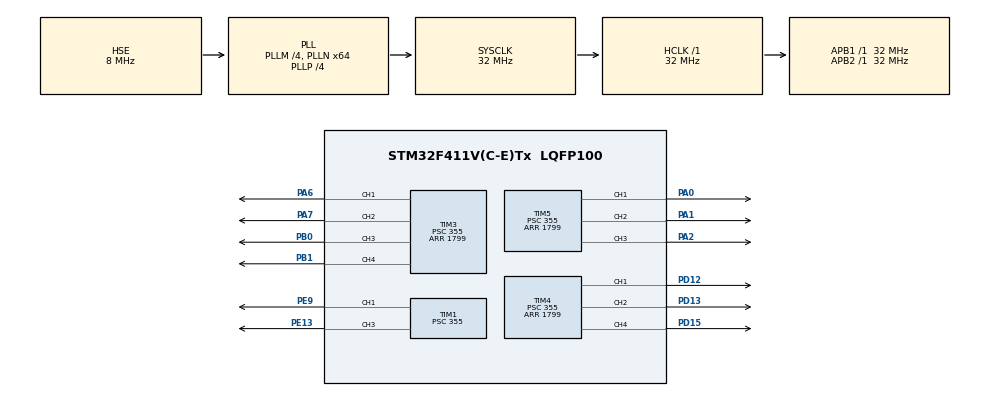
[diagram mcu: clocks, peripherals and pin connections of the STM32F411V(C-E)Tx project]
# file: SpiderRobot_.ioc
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Mcu.Family=STM32F4
Mcu.Name=STM32F411V(C-E)Tx
Mcu.Package=LQFP100
NVIC.PriorityGroup=NVIC_PRIORITYGROUP_4
PA0-WKUP.Signal=S_TIM5_CH1
PA1.Signal=S_TIM5_CH2
PA13.Mode=Serial_Wire
PA13.Signal=SYS_JTMS-SWDIO
PA14.Mode=Serial_Wire
PA14.Signal=SYS_JTCK-SWCLK
PA2.Signal=S_TIM5_CH3
PA6.Signal=S_TIM3_CH1
PA7.Signal=S_TIM3_CH2
PB0.Signal=S_TIM3_CH3
PB1.Signal=S_TIM3_CH4
PD12.Signal=S_TIM4_CH1
PD13.Signal=S_TIM4_CH2
PD15.Signal=S_TIM4_CH4
PE13.Signal=S_TIM1_CH3
PE9.Signal=S_TIM1_CH1
PH0\ -\ OSC_IN.Mode=HSE-External-Oscillator
PH0\ -\ OSC_IN.Signal=RCC_OSC_IN
PH1\ -\ OSC_OUT.Mode=HSE-External-Oscillator
PH1\ -\ OSC_OUT.Signal=RCC_OSC_OUT
ProjectManager.HeapSize=0x200
ProjectManager.StackSize=0x400
ProjectManager.TargetToolchain=STM32CubeIDE
RCC.48MHZClocksFreq_Value=32000000
RCC.AHBFreq_Value=32000000
RCC.APB1Freq_Value=32000000
RCC.APB1TimFreq_Value=32000000
RCC.APB2Freq_Value=32000000
RCC.APB2TimFreq_Value=32000000
RCC.CortexFreq_Value=32000000
RCC.HCLKFreq_Value=32000000
RCC.HSE_VALUE=8000000
RCC.HSI_VALUE=16000000
RCC.LSE_VALUE=32768
RCC.PLLM=4
RCC.PLLN=64
RCC.PLLP=RCC_PLLP_DIV4
RCC.PLLSourceVirtual=RCC_PLLSOURCE_HSE
RCC.SYSCLKFreq_VALUE=32000000
RCC.SYSCLKSource=RCC_SYSCLKSOURCE_PLLCLK
RCC.VCOOutputFreq_Value=128000000
SH.S_TIM1_CH1.0=TIM1_CH1,PWM Generation1 CH1
SH.S_TIM1_CH3.0=TIM1_CH3,PWM Generation3 CH3
SH.S_TIM3_CH1.0=TIM3_CH1,PWM Generation1 CH1
SH.S_TIM3_CH2.0=TIM3_CH2,PWM Generation2 CH2
SH.S_TIM3_CH3.0=TIM3_CH3,PWM Generation3 CH3
SH.S_TIM3_CH4.0=TIM3_CH4,PWM Generation4 CH4
SH.S_TIM4_CH1.0=TIM4_CH1,PWM Generation1 CH1
SH.S_TIM4_CH2.0=TIM4_CH2,PWM Generation2 CH2
SH.S_TIM4_CH4.0=TIM4_CH4,PWM Generation4 CH4
SH.S_TIM5_CH1.0=TIM5_CH1,PWM Generation1 CH1
SH.S_TIM5_CH2.0=TIM5_CH2,PWM Generation2 CH2
SH.S_TIM5_CH3.0=TIM5_CH3,PWM Generation3 CH3
TIM1.Channel-PWM\ Generation1\ CH1=TIM_CHANNEL_1
TIM1.Channel-PWM\ Generation3\ CH3=TIM_CHANNEL_3
TIM1.Period=1799
TIM1.Prescaler=355
TIM3.Channel-PWM\ Generation1\ CH1=TIM_CHANNEL_1
TIM3.Channel-PWM\ Generation2\ CH2=TIM_CHANNEL_2
TIM3.Channel-PWM\ Generation3\ CH3=TIM_CHANNEL_3
TIM3.Channel-PWM\ Generation4\ CH4=TIM_CHANNEL_4
TIM3.Period=1799
TIM3.Prescaler=355
TIM4.Channel-PWM\ Generation1\ CH1=TIM_CHANNEL_1
TIM4.Channel-PWM\ Generation2\ CH2=TIM_CHANNEL_2
TIM4.Channel-PWM\ Generation3\ CH3=TIM_CHANNEL_3
TIM4.Channel-PWM\ Generation4\ CH4=TIM_CHANNEL_4
TIM4.Period=1799
TIM4.Prescaler=355
TIM5.Channel-PWM\ Generation1\ CH1=TIM_CHANNEL_1
TIM5.Channel-PWM\ Generation2\ CH2=TIM_CHANNEL_2
TIM5.Channel-PWM\ Generation3\ CH3=TIM_CHANNEL_3
TIM5.Period=1799
TIM5.Prescaler=355
board=custom

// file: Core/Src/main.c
/* USER CODE BEGIN Header */
/**
  ******************************************************************************
  * @file           : main.c
  * @brief          : Main program body
  ******************************************************************************
  * @attention
  *
  * Copyright (c) 2022 STMicroelectronics.
  * All rights reserved.
  *
  * This software is licensed under terms that can be found in the LICENSE file
  * in the root directory of this software component.
  * If no LICENSE file comes with this software, it is provided AS-IS.
  *
  ******************************************************************************
  */
/* USER CODE END Header */
#include "SpiderDriver.h"
#include "main.h"

TIM_HandleTypeDef htim1;
TIM_HandleTypeDef htim3;
TIM_HandleTypeDef htim4;
TIM_HandleTypeDef htim5;

void SystemClock_Config(void);
static void MX_GPIO_Init(void);
static void MX_TIM1_Init(void);
static void MX_TIM3_Init(void);
static void MX_TIM4_Init(void);
static void MX_TIM5_Init(void);

int main(void)
{

  /* MCU Configuration--------------------------------------------------------*/

  /* Reset of all peripherals, Initializes the Flash interface and the Systick. */
  HAL_Init();

  /* Configure the system clock */
  SystemClock_Config();

  /* Initialize all configured peripherals */
  MX_GPIO_Init();
  MX_TIM1_Init();
  MX_TIM3_Init();
  MX_TIM4_Init();
  MX_TIM5_Init();

  /* USER CODE BEGIN 2 */

  robot_tims_init();
  HAL_Delay(50);

  robot_all_leg_90();
  HAL_Delay(1000);

  initPosition();
  HAL_Delay(1000);

  /* USER CODE END 2 */

  /* Infinite loop */
  while (1)
  {

    /* USER CODE BEGIN 3 */

	  moveForward();

  }
  /* USER CODE END 3 */
}

void SystemClock_Config(void)
{
  RCC_OscInitTypeDef RCC_OscInitStruct = {0};
  RCC_ClkInitTypeDef RCC_ClkInitStruct = {0};

  /** Configure the main internal regulator output voltage
  */
  __HAL_RCC_PWR_CLK_ENABLE();
  __HAL_PWR_VOLTAGESCALING_CONFIG(PWR_REGULATOR_VOLTAGE_SCALE1);

  /** Initializes the RCC Oscillators according to the specified parameters
  * in the RCC_OscInitTypeDef structure.
  */
  RCC_OscInitStruct.OscillatorType = RCC_OSCILLATORTYPE_HSE;
  RCC_OscInitStruct.HSEState = RCC_HSE_ON;
  RCC_OscInitStruct.PLL.PLLState = RCC_PLL_ON;
  RCC_OscInitStruct.PLL.PLLSource = RCC_PLLSOURCE_HSE;
  RCC_OscInitStruct.PLL.PLLM = 4;
  RCC_OscInitStruct.PLL.PLLN = 64;
  RCC_OscInitStruct.PLL.PLLP = RCC_PLLP_DIV4;
  RCC_OscInitStruct.PLL.PLLQ = 4;
  if (HAL_RCC_OscConfig(&RCC_OscInitStruct) != HAL_OK)
  {
    Error_Handler();
  }

  /** Initializes the CPU, AHB and APB buses clocks
  */
  RCC_ClkInitStruct.ClockType = RCC_CLOCKTYPE_HCLK|RCC_CLOCKTYPE_SYSCLK
                              |RCC_CLOCKTYPE_PCLK1|RCC_CLOCKTYPE_PCLK2;
  RCC_ClkInitStruct.SYSCLKSource = RCC_SYSCLKSOURCE_PLLCLK;
  RCC_ClkInitStruct.AHBCLKDivider = RCC_SYSCLK_DIV1;
  RCC_ClkInitStruct.APB1CLKDivider = RCC_HCLK_DIV1;
  RCC_ClkInitStruct.APB2CLKDivider = RCC_HCLK_DIV1;

  if (HAL_RCC_ClockConfig(&RCC_ClkInitStruct, FLASH_LATENCY_1) != HAL_OK)
  {
    Error_Handler();
  }
}

static void MX_TIM1_Init(void)
{

  TIM_MasterConfigTypeDef sMasterConfig = {0};
  TIM_OC_InitTypeDef sConfigOC = {0};
  TIM_BreakDeadTimeConfigTypeDef sBreakDeadTimeConfig = {0};

  htim1.Instance = TIM1;
  htim1.Init.Prescaler = 355;
  htim1.Init.CounterMode = TIM_COUNTERMODE_UP;
  htim1.Init.Period = 1799;
  htim1.Init.ClockDivision = TIM_CLOCKDIVISION_DIV1;
  htim1.Init.RepetitionCounter = 0;
  htim1.Init.AutoReloadPreload = TIM_AUTORELOAD_PRELOAD_DISABLE;
  if (HAL_TIM_PWM_Init(&htim1) != HAL_OK)
  {
    Error_Handler();
  }
  sMasterConfig.MasterOutputTrigger = TIM_TRGO_RESET;
  sMasterConfig.MasterSlaveMode = TIM_MASTERSLAVEMODE_DISABLE;
  if (HAL_TIMEx_MasterConfigSynchronization(&htim1, &sMasterConfig) != HAL_OK)
  {
    Error_Handler();
  }
  sConfigOC.OCMode = TIM_OCMODE_PWM1;
  sConfigOC.Pulse = 0;
  sConfigOC.OCPolarity = TIM_OCPOLARITY_HIGH;
  sConfigOC.OCNPolarity = TIM_OCNPOLARITY_HIGH;
  sConfigOC.OCFastMode = TIM_OCFAST_DISABLE;
  sConfigOC.OCIdleState = TIM_OCIDLESTATE_RESET;
  sConfigOC.OCNIdleState = TIM_OCNIDLESTATE_RESET;
  if (HAL_TIM_PWM_ConfigChannel(&htim1, &sConfigOC, TIM_CHANNEL_1) != HAL_OK)
  {
    Error_Handler();
  }
  if (HAL_TIM_PWM_ConfigChannel(&htim1, &sConfigOC, TIM_CHANNEL_3) != HAL_OK)
  {
    Error_Handler();
  }
  sBreakDeadTimeConfig.OffStateRunMode = TIM_OSSR_DISABLE;
  sBreakDeadTimeConfig.OffStateIDLEMode = TIM_OSSI_DISABLE;
  sBreakDeadTimeConfig.LockLevel = TIM_LOCKLEVEL_OFF;
  sBreakDeadTimeConfig.DeadTime = 0;
  sBreakDeadTimeConfig.BreakState = TIM_BREAK_DISABLE;
  sBreakDeadTimeConfig.BreakPolarity = TIM_BREAKPOLARITY_HIGH;
  sBreakDeadTimeConfig.AutomaticOutput = TIM_AUTOMATICOUTPUT_DISABLE;
  if (HAL_TIMEx_ConfigBreakDeadTime(&htim1, &sBreakDeadTimeConfig) != HAL_OK)
  {
    Error_Handler();
  }
  HAL_TIM_MspPostInit(&htim1);

}

static void MX_TIM3_Init(void)
{

  TIM_MasterConfigTypeDef sMasterConfig = {0};
  TIM_OC_InitTypeDef sConfigOC = {0};

  htim3.Instance = TIM3;
  htim3.Init.Prescaler = 355;
  htim3.Init.CounterMode = TIM_COUNTERMODE_UP;
  htim3.Init.Period = 1799;
  htim3.Init.ClockDivision = TIM_CLOCKDIVISION_DIV1;
  htim3.Init.AutoReloadPreload = TIM_AUTORELOAD_PRELOAD_DISABLE;
  if (HAL_TIM_PWM_Init(&htim3) != HAL_OK)
  {
    Error_Handler();
  }
  sMasterConfig.MasterOutputTrigger = TIM_TRGO_RESET;
  sMasterConfig.MasterSlaveMode = TIM_MASTERSLAVEMODE_DISABLE;
  if (HAL_TIMEx_MasterConfigSynchronization(&htim3, &sMasterConfig) != HAL_OK)
  {
    Error_Handler();
  }
  sConfigOC.OCMode = TIM_OCMODE_PWM1;
  sConfigOC.Pulse = 0;
  sConfigOC.OCPolarity = TIM_OCPOLARITY_HIGH;
  sConfigOC.OCFastMode = TIM_OCFAST_DISABLE;
  if (HAL_TIM_PWM_ConfigChannel(&htim3, &sConfigOC, TIM_CHANNEL_1) != HAL_OK)
  {
    Error_Handler();
  }
  if (HAL_TIM_PWM_ConfigChannel(&htim3, &sConfigOC, TIM_CHANNEL_2) != HAL_OK)
  {
    Error_Handler();
  }
  if (HAL_TIM_PWM_ConfigChannel(&htim3, &sConfigOC, TIM_CHANNEL_3) != HAL_OK)
  {
    Error_Handler();
  }
  if (HAL_TIM_PWM_ConfigChannel(&htim3, &sConfigOC, TIM_CHANNEL_4) != HAL_OK)
  {
    Error_Handler();
  }
  HAL_TIM_MspPostInit(&htim3);

}

static void MX_TIM4_Init(void)
{

  TIM_MasterConfigTypeDef sMasterConfig = {0};
  TIM_OC_InitTypeDef sConfigOC = {0};

  htim4.Instance = TIM4;
  htim4.Init.Prescaler = 355;
  htim4.Init.CounterMode = TIM_COUNTERMODE_UP;
  htim4.Init.Period = 1799;
  htim4.Init.ClockDivision = TIM_CLOCKDIVISION_DIV1;
  htim4.Init.AutoReloadPreload = TIM_AUTORELOAD_PRELOAD_DISABLE;
  if (HAL_TIM_PWM_Init(&htim4) != HAL_OK)
  {
    Error_Handler();
  }
  sMasterConfig.MasterOutputTrigger = TIM_TRGO_RESET;
  sMasterConfig.MasterSlaveMode = TIM_MASTERSLAVEMODE_DISABLE;
  if (HAL_TIMEx_MasterConfigSynchronization(&htim4, &sMasterConfig) != HAL_OK)
  {
    Error_Handler();
  }
  sConfigOC.OCMode = TIM_OCMODE_PWM1;
  sConfigOC.Pulse = 0;
  sConfigOC.OCPolarity = TIM_OCPOLARITY_HIGH;
  sConfigOC.OCFastMode = TIM_OCFAST_DISABLE;
  if (HAL_TIM_PWM_ConfigChannel(&htim4, &sConfigOC, TIM_CHANNEL_1) != HAL_OK)
  {
    Error_Handler();
  }
  if (HAL_TIM_PWM_ConfigChannel(&htim4, &sConfigOC, TIM_CHANNEL_2) != HAL_OK)
  {
    Error_Handler();
  }
  if (HAL_TIM_PWM_ConfigChannel(&htim4, &sConfigOC, TIM_CHANNEL_4) != HAL_OK)
  {
    Error_Handler();
  }
  HAL_TIM_MspPostInit(&htim4);

}

static void MX_TIM5_Init(void)
{

  TIM_MasterConfigTypeDef sMasterConfig = {0};
  TIM_OC_InitTypeDef sConfigOC = {0};

  htim5.Instance = TIM5;
  htim5.Init.Prescaler = 355;
  htim5.Init.CounterMode = TIM_COUNTERMODE_UP;
  htim5.Init.Period = 1799;
  htim5.Init.ClockDivision = TIM_CLOCKDIVISION_DIV1;
  htim5.Init.AutoReloadPreload = TIM_AUTORELOAD_PRELOAD_DISABLE;
  if (HAL_TIM_PWM_Init(&htim5) != HAL_OK)
  {
    Error_Handler();
  }
  sMasterConfig.MasterOutputTrigger = TIM_TRGO_RESET;
  sMasterConfig.MasterSlaveMode = TIM_MASTERSLAVEMODE_DISABLE;
  if (HAL_TIMEx_MasterConfigSynchronization(&htim5, &sMasterConfig) != HAL_OK)
  {
    Error_Handler();
  }
  sConfigOC.OCMode = TIM_OCMODE_PWM1;
  sConfigOC.Pulse = 0;
  sConfigOC.OCPolarity = TIM_OCPOLARITY_HIGH;
  sConfigOC.OCFastMode = TIM_OCFAST_DISABLE;
  if (HAL_TIM_PWM_ConfigChannel(&htim5, &sConfigOC, TIM_CHANNEL_1) != HAL_OK)
  {
    Error_Handler();
  }
  if (HAL_TIM_PWM_ConfigChannel(&htim5, &sConfigOC, TIM_CHANNEL_2) != HAL_OK)
  {
    Error_Handler();
  }
  if (HAL_TIM_PWM_ConfigChannel(&htim5, &sConfigOC, TIM_CHANNEL_3) != HAL_OK)
  {
    Error_Handler();
  }
  HAL_TIM_MspPostInit(&htim5);

}

static void MX_GPIO_Init(void)
{

  /* GPIO Ports Clock Enable */
  __HAL_RCC_GPIOH_CLK_ENABLE();
  __HAL_RCC_GPIOA_CLK_ENABLE();
  __HAL_RCC_GPIOB_CLK_ENABLE();
  __HAL_RCC_GPIOE_CLK_ENABLE();
  __HAL_RCC_GPIOD_CLK_ENABLE();

}

/* USER CODE BEGIN 4 */
//void initPosition(){
//
//int t=300;
//
//leg1_3(d);
//HAL_Delay(t);
//leg2_3(b);
//HAL_Delay(t);
//leg3_3(b);
//HAL_Delay(t);
//leg4_3(d);
//HAL_Delay(t);
//
//leg1_2(b);
//HAL_Delay(t);
//leg2_2(d);
//HAL_Delay(t);
//leg3_2(d);
//HAL_Delay(t);
//leg4_2(b);
//HAL_Delay(t);
//
//leg1_1(b);
//HAL_Delay(t);
//leg2_1(d);
//HAL_Delay(t);
//leg3_1(d);
//HAL_Delay(t);
//leg4_1(b);
//HAL_Delay(t);
//
//
//}
//
//void moveForward(){
//	int delay=200;
//	leg2_2(e);
//	HAL_Delay(delay);
//	leg2_3(a);
//	leg2_1(c);
//	HAL_Delay(delay);
//	leg2_2(d);
//	HAL_Delay(delay);
//
//
//	leg1_3(c+20);//
//	leg3_3(a-20);
//	leg4_3(e);
//	leg1_1(a);
//	leg2_1(d);
//	leg3_1(c);
//	leg4_1(c+10);
//	HAL_Delay(delay);
//
//
//	leg3_2(e);
//	HAL_Delay(delay);
//	leg3_3(c-20);
//	leg3_1(d);
//	HAL_Delay(delay);
//	leg3_2(d);
//	HAL_Delay(delay);
//
//	/*    */
//
//
//	leg1_2(a);
//	HAL_Delay(delay);
//	leg1_3(e+20);//
//	leg1_1(b);
//	HAL_Delay(delay);
//	leg1_2(b);
//	HAL_Delay(delay);
//
//
//	leg1_3(d+20);
//	leg2_3(b);
//	leg3_3(b-20);
//	leg4_2(c);
//	leg1_1(b);//b
//	leg4_1(d+10);
//	HAL_Delay(delay);
//
//
//	leg4_2(a);
//	HAL_Delay(delay);
//	leg4_3(d);
//	leg4_1(b+10);
//	HAL_Delay(delay);
//	leg4_2(b);
//	HAL_Delay(delay);
//}
//
//void kademeliArttir(TIM_HandleTypeDef timer,unsigned int chanel, int bacak, int eklem, int angle, int fark){
//	int i;
//	int current = currentPosition[bacak][eklem];
//
//	if(current == angle){
//		__HAL_TIM_SET_COMPARE(&timer, chanel, current);
//		return;
//	}
//
//	if(current < angle){
//		for(i=current; i<=angle; i++){
//			HAL_Delay(3);
//			__HAL_TIM_SET_COMPARE(&timer, chanel, i);
//		}
//		currentPosition[bacak][eklem] = angle;
//	}
//	else{
//		for(i=current; i>=angle; i--){
//
//			HAL_Delay(3);
//			__HAL_TIM_SET_COMPARE(&timer, chanel, i);
//		}
//		currentPosition[bacak][eklem] = angle;
//	}
//
//}
//
//
//void leg4_1(int angle){
//
//	if(angle < 0)
//		 angle = 0;
//	if(angle >180)
//		angle = 180;
//	angle = angle + 45;
//	kademeliArttir(htim5, TIM_CHANNEL_2, 4, 1, angle, 45);
//
//	//__HAL_TIM_SET_COMPARE(&htim5, TIM_CHANNEL_2, angle);
//
//}
//
//void leg4_2(int angle){
//
//	if(angle < 0)
//		 angle = 0;
//	if(angle >180)
//		angle = 180;
//	angle = angle + 37;//37
//	//kademeliArttir(htim3,TIM_CHANNEL_2, 4, 2, angle, 37);
//	__HAL_TIM_SET_COMPARE(&htim3, TIM_CHANNEL_2, angle);
//
//}
//
//
//void leg4_3(int angle){
//
//	if(angle < 0)
//		 angle = 0;
//	if(angle >180)
//		angle = 180;
//	angle = angle + 45;
//	kademeliArttir(htim1, TIM_CHANNEL_1, 4, 3, angle, 45);
//	//__HAL_TIM_SET_COMPARE(&htim1, TIM_CHANNEL_1, angle);
//
//}
//
//
//void leg2_1(int angle){
//
//	if(angle < 0)
//		 angle = 0;
//	if(angle >180)
//		angle = 180;
//	angle = angle + 45;
//	kademeliArttir(htim1, TIM_CHANNEL_3, 2, 1, angle, 45);
//	//__HAL_TIM_SET_COMPARE(&htim1, TIM_CHANNEL_3, angle);
//}
//
//
//void leg2_2(int angle){
//
//	if(angle < 0)
//		 angle = 0;
//	if(angle >180)
//		angle = 180;
//	angle = angle + 47;
//	kademeliArttir(htim5, TIM_CHANNEL_3, 2, 2, angle, 47);
//	//__HAL_TIM_SET_COMPARE(&htim5, TIM_CHANNEL_3, angle);
//}
//
//
//void leg2_3(int angle){
//
//	if(angle < 0)
//		 angle = 0;
//	if(angle >180)
//		angle = 180;
//	angle = angle + 32;
//	kademeliArttir(htim5, TIM_CHANNEL_1, 2, 3, angle, 32);
//	//__HAL_TIM_SET_COMPARE(&htim5, TIM_CHANNEL_1, angle);
//}
//
//
//void leg3_1(int angle){
//
//	if(angle < 0)
//		 angle = 0;
//	if(angle >180)
//		angle = 180;
//	angle = angle + 45;
//	kademeliArttir(htim4, TIM_CHANNEL_4, 3, 1, angle, 45);
//	//__HAL_TIM_SET_COMPARE(&htim4, TIM_CHANNEL_4, angle);
//
//}
//
//
//void leg3_2(int angle){
//
//	if(angle < 0)
//		 angle = 0;
//	if(angle >180)
//		angle = 180;
//	angle = angle + 47;
//	kademeliArttir(htim4, TIM_CHANNEL_2, 3, 2, angle, 47);
//	//__HAL_TIM_SET_COMPARE(&htim4, TIM_CHANNEL_2, angle);
//
//}
//
//
////void leg3_3(int angle){
////
////	if(angle < 0)
////		 angle = 0;
////	if(angle >180)
////		angle = 180;
////	angle = angle + 37;//37
////	kademeliArttir(htim3, TIM_CHANNEL_4, 3, 3, angle, 37);
//////	__HAL_TIM_SET_COMPARE(&htim1, TIM_CHANNEL_2, angle);
////}
//
//
//
//void leg3_3(int angle){
//	if(angle < 0)
//		 angle = 0;
//	if(angle >180)
//		angle = 180;
//	angle = angle + 37;
//	kademeliArttir(htim3, TIM_CHANNEL_4, 3, 3, angle, 37);
//	//__HAL_TIM_SET_COMPARE(&htim1, TIM_CHANNEL_2, angle);
//}
//
//void leg1_1(int angle){
//	if(angle < 0)
//		 angle = 0;
//	if(angle >180)
//		angle = 180;
//	angle = angle + 35;
//	kademeliArttir(htim4, TIM_CHANNEL_1, 1, 1, angle, 35);
//	//__HAL_TIM_SET_COMPARE(&htim4, TIM_CHANNEL_1, angle);
//}
//
//
//void leg1_2(int angle){
//	if(angle < 0)
//		 angle = 0;
//	if(angle >180)
//		angle = 180;
//	angle = angle + 48;
//	kademeliArttir(htim3, TIM_CHANNEL_3, 1, 2, angle, 48);
//	//__HAL_TIM_SET_COMPARE(&htim3, TIM_CHANNEL_3, angle);
//}
//
//
//void leg1_3(int angle){
//	if(angle < 0)
//		 angle = 0;
//	if(angle >180)
//		angle = 180;
//	angle = angle + 48;
//	kademeliArttir(htim3, TIM_CHANNEL_1, 1, 3, angle, 48);
//	//__HAL_TIM_SET_COMPARE(&htim3, TIM_CHANNEL_1, angle);
//}
//
//void robot_all_leg_90(void){
//
//	int i = 90;
//
//	  leg1_1(i);
//	  HAL_Delay(500);
//	  leg1_2(i);
//	  HAL_Delay(500);
//	  leg1_3(i);
//	  HAL_Delay(1500);
//
//
//	  leg2_1(i);
//	  HAL_Delay(500);
//	  leg2_2(i);
//	  HAL_Delay(500);
//	  leg2_3(i);
//	  HAL_Delay(1500);
//
//	  leg3_1(i);
//	  HAL_Delay(500);
//	  leg3_2(i);
//	  HAL_Delay(500);
//	  leg3_3(i);
//	  HAL_Delay(1500);
//
//	  leg4_1(i);
//	  HAL_Delay(500);
//	  leg4_2(i);
//	  HAL_Delay(500);
//	  leg4_3(i);
//	  HAL_Delay(1500);
//
//}
//
//void robot_all_leg_init(void){
//
//	  leg1_1(115);
//	  HAL_Delay(500);
//	  leg1_2(120);
//	  HAL_Delay(500);
//	  leg1_3(140);
//	  HAL_Delay(500);
//
//	  leg4_1(115);
//	  HAL_Delay(500);
//	  leg4_2(120);
//	  HAL_Delay(500);
//	  leg4_3(140);
//	  HAL_Delay(500);
//
//
//	  leg2_1(65);
//	  HAL_Delay(500);
//	  leg2_2(60);
//	  HAL_Delay(500);
//	  leg2_3(40);
//	  HAL_Delay(500);
//
//	  leg3_1(65);
//	  HAL_Delay(500);
//	  leg3_2(60);
//	  HAL_Delay(500);
//	  leg3_3(40);
//	  HAL_Delay(500);
//
//
//}
//
//
//
//void robot_tims_init(void){
//
//
//	  HAL_TIM_PWM_Start(&htim1, TIM_CHANNEL_1);
//	  HAL_TIM_PWM_Start(&htim1, TIM_CHANNEL_3);
//
//	  HAL_TIM_PWM_Start(&htim3, TIM_CHANNEL_1);
//	  HAL_TIM_PWM_Start(&htim3, TIM_CHANNEL_2);
//	  HAL_TIM_PWM_Start(&htim3, TIM_CHANNEL_3);
//	  HAL_TIM_PWM_Start(&htim3, TIM_CHANNEL_4);
//
//
//	  HAL_TIM_PWM_Start(&htim4, TIM_CHANNEL_1);
//	  HAL_TIM_PWM_Start(&htim4, TIM_CHANNEL_2);
//	  HAL_TIM_PWM_Start(&htim4, TIM_CHANNEL_4);
//
//	  HAL_TIM_PWM_Start(&htim5, TIM_CHANNEL_1);
//	  HAL_TIM_PWM_Start(&htim5, TIM_CHANNEL_2);
//	  HAL_TIM_PWM_Start(&htim5, TIM_CHANNEL_3);
//
//
//}

/* USER CODE END 4 */

void Error_Handler(void)
{
  __disable_irq();
  while (1)
  {
  }
}
